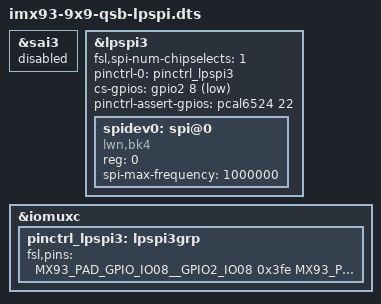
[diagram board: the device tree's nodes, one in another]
// SPDX-License-Identifier: (GPL-2.0+ OR MIT)
/*
 * Copyright 2022 NXP
 */

#include "imx93-9x9-qsb.dts"

&sai3 {
	status = "disabled";
};

&lpspi3 {
	fsl,spi-num-chipselects = <1>;
	pinctrl-names = "default";
	pinctrl-0 = <&pinctrl_lpspi3>;
	cs-gpios = <&gpio2 8 GPIO_ACTIVE_LOW>;
	/*
	 * Switch the SPI pins to RPi connector for testing.
	 * It will also control the pins of SAI3, so SAI3 is disabled above.
	 */
	pinctrl-assert-gpios = <&pcal6524 22 GPIO_ACTIVE_HIGH>;
	status = "okay";

	spidev0: spi@0 {
		reg = <0>;
		compatible = "lwn,bk4";
		spi-max-frequency = <1000000>;
	};
};

&iomuxc {
	pinctrl_lpspi3: lpspi3grp {
		fsl,pins = <
			MX93_PAD_GPIO_IO08__GPIO2_IO08		0x3fe
			MX93_PAD_GPIO_IO09__LPSPI3_SIN		0x3fe
			MX93_PAD_GPIO_IO10__LPSPI3_SOUT		0x3fe
			MX93_PAD_GPIO_IO11__LPSPI3_SCK		0x3fe
		>;
	};
};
